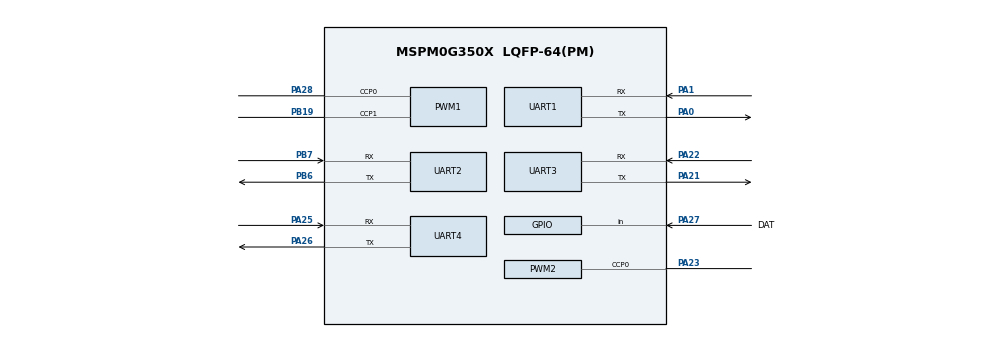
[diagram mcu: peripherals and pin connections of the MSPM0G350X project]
/**
 * @cliArgs --device "MSPM0G350X" --package "LQFP-64(PM)" --part "Default" --product "mspm0_sdk@2.01.00.03"
 * @versions {"tool":"1.20.0+3587"}
 */

/**
 * Import the modules used in this configuration.
 */
const GPIO    = scripting.addModule("/ti/driverlib/GPIO", {}, false);
const GPIO1   = GPIO.addInstance();
const GPIO2   = GPIO.addInstance();
const GPIO3   = GPIO.addInstance();
const GPIO4   = GPIO.addInstance();
const GPIO5   = GPIO.addInstance();
const GPIO6   = GPIO.addInstance();
const GPIO7   = GPIO.addInstance();
const PWM     = scripting.addModule("/ti/driverlib/PWM", {}, false);
const PWM1    = PWM.addInstance();
const PWM2    = PWM.addInstance();
const SYSCTL  = scripting.addModule("/ti/driverlib/SYSCTL");
const SYSTICK = scripting.addModule("/ti/driverlib/SYSTICK");
const TIMER   = scripting.addModule("/ti/driverlib/TIMER", {}, false);
const TIMER1  = TIMER.addInstance();
const UART    = scripting.addModule("/ti/driverlib/UART", {}, false);
const UART1   = UART.addInstance();
const UART2   = UART.addInstance();
const UART3   = UART.addInstance();
const UART4   = UART.addInstance();

/**
 * Write custom configuration values to the imported modules.
 */
const gate7  = system.clockTree["MFCLKGATE"];
gate7.enable = true;

GPIO1.$name                          = "GPIO_MOTOR";
GPIO1.associatedPins.create(4);
GPIO1.associatedPins[0].assignedPort = "PORTA";
GPIO1.associatedPins[0].initialValue = "SET";
GPIO1.associatedPins[0].$name        = "PIN_FL1";
GPIO1.associatedPins[0].assignedPin  = "2";
GPIO1.associatedPins[1].assignedPort = "PORTA";
GPIO1.associatedPins[1].initialValue = "SET";
GPIO1.associatedPins[1].$name        = "PIN_FL2";
GPIO1.associatedPins[1].assignedPin  = "31";
GPIO1.associatedPins[2].$name        = "PIN_FR1";
GPIO1.associatedPins[2].assignedPort = "PORTB";
GPIO1.associatedPins[2].assignedPin  = "24";
GPIO1.associatedPins[3].$name        = "PIN_FR2";
GPIO1.associatedPins[3].assignedPort = "PORTB";
GPIO1.associatedPins[3].assignedPin  = "20";

const Board = scripting.addModule("/ti/driverlib/Board", {}, false);

GPIO2.$name                          = "GPIO_Encoder";
GPIO2.associatedPins.create(4);
GPIO2.associatedPins[0].$name        = "PIN_Left_A";
GPIO2.associatedPins[0].direction    = "INPUT";
GPIO2.associatedPins[0].assignedPort = "PORTA";
GPIO2.associatedPins[0].assignedPin  = "7";
GPIO2.associatedPins[0].interruptEn  = true;
GPIO2.associatedPins[0].polarity     = "RISE";
GPIO2.associatedPins[1].$name        = "PIN_Right_A";
GPIO2.associatedPins[1].direction    = "INPUT";
GPIO2.associatedPins[1].assignedPort = "PORTB";
GPIO2.associatedPins[1].assignedPin  = "3";
GPIO2.associatedPins[1].interruptEn  = true;
GPIO2.associatedPins[1].polarity     = "RISE";
GPIO2.associatedPins[2].$name        = "PIN_Left_B";
GPIO2.associatedPins[2].direction    = "INPUT";
GPIO2.associatedPins[2].assignedPort = "PORTB";
GPIO2.associatedPins[2].assignedPin  = "18";
GPIO2.associatedPins[3].$name        = "PIN_Right_B";
GPIO2.associatedPins[3].direction    = "INPUT";
GPIO2.associatedPins[3].assignedPort = "PORTB";
GPIO2.associatedPins[3].assignedPin  = "2";

GPIO3.$name                          = "GPIO_SWITCHES";
GPIO3.associatedPins[0].$name        = "USER_SWITCH_1";
GPIO3.associatedPins[0].direction    = "INPUT";
GPIO3.associatedPins[0].assignedPort = "PORTA";
GPIO3.associatedPins[0].assignedPin  = "18";

GPIO4.$name                          = "GPIO_LEDS";
GPIO4.associatedPins[0].$name        = "USR_LED_1";
GPIO4.associatedPins[0].initialValue = "SET";
GPIO4.associatedPins[0].assignedPort = "PORTA";
GPIO4.associatedPins[0].assignedPin  = "14";

GPIO5.$name                               = "GPIO_GanWei";
GPIO5.port                                = "PORTA";
GPIO5.associatedPins.create(2);
GPIO5.associatedPins[0].$name             = "CLK";
GPIO5.associatedPins[0].assignedPin       = "24";
GPIO5.associatedPins[1].$name             = "DAT";
GPIO5.associatedPins[1].direction         = "INPUT";
GPIO5.associatedPins[1].internalResistor  = "PULL_UP";
GPIO5.associatedPins[1].assignedPin       = "27";
GPIO5.associatedPins[1].interruptEn       = true;
GPIO5.associatedPins[1].interruptPriority = "0";
GPIO5.associatedPins[1].polarity          = "RISE";
GPIO5.associatedPins[1].pin.$assign       = "PA27";

GPIO6.$name                          = "GPIO_Light";
GPIO6.associatedPins.create(5);
GPIO6.associatedPins[0].$name        = "PIN_Light_1";
GPIO6.associatedPins[0].direction    = "INPUT";
GPIO6.associatedPins[0].assignedPort = "PORTA";
GPIO6.associatedPins[0].assignedPin  = "8";
GPIO6.associatedPins[1].$name        = "PIN_Light_2";
GPIO6.associatedPins[1].direction    = "INPUT";
GPIO6.associatedPins[1].assignedPort = "PORTA";
GPIO6.associatedPins[1].assignedPin  = "9";
GPIO6.associatedPins[2].$name        = "PIN_Light_3";
GPIO6.associatedPins[2].direction    = "INPUT";
GPIO6.associatedPins[2].assignedPort = "PORTA";
GPIO6.associatedPins[2].assignedPin  = "13";
GPIO6.associatedPins[3].$name        = "PIN_Light_4";
GPIO6.associatedPins[3].direction    = "INPUT";
GPIO6.associatedPins[3].assignedPort = "PORTA";
GPIO6.associatedPins[3].assignedPin  = "12";
GPIO6.associatedPins[4].$name        = "PIN_Light_5";
GPIO6.associatedPins[4].direction    = "INPUT";
GPIO6.associatedPins[4].assignedPort = "PORTA";
GPIO6.associatedPins[4].assignedPin  = "15";

GPIO7.$name                          = "GPIO_Jidianqi";
GPIO7.associatedPins[0].$name        = "GPIO_Ji";
GPIO7.associatedPins[0].initialValue = "SET";
GPIO7.associatedPins[0].assignedPort = "PORTA";
GPIO7.associatedPins[0].assignedPin  = "16";

PWM1.$name                              = "PWM_MOTOR";
PWM1.timerCount                         = 32000;
PWM1.timerStartTimer                    = true;
PWM1.peripheral.$assign                 = "TIMG7";
PWM1.peripheral.ccp0Pin.$assign         = "PA28";
PWM1.peripheral.ccp1Pin.$assign         = "PB19";
PWM1.PWM_CHANNEL_0.$name                = "ti_driverlib_pwm_PWMTimerCC0";
PWM1.PWM_CHANNEL_0.ccValue              = 3199;
PWM1.PWM_CHANNEL_1.$name                = "ti_driverlib_pwm_PWMTimerCC1";
PWM1.ccp0PinConfig.direction            = scripting.forceWrite("OUTPUT");
PWM1.ccp0PinConfig.hideOutputInversion  = scripting.forceWrite(false);
PWM1.ccp0PinConfig.onlyInternalResistor = scripting.forceWrite(false);
PWM1.ccp0PinConfig.passedPeripheralType = scripting.forceWrite("Digital");
PWM1.ccp0PinConfig.$name                = "ti_driverlib_gpio_GPIOPinGeneric10";
PWM1.ccp1PinConfig.direction            = scripting.forceWrite("OUTPUT");
PWM1.ccp1PinConfig.hideOutputInversion  = scripting.forceWrite(false);
PWM1.ccp1PinConfig.onlyInternalResistor = scripting.forceWrite(false);
PWM1.ccp1PinConfig.passedPeripheralType = scripting.forceWrite("Digital");
PWM1.ccp1PinConfig.$name                = "ti_driverlib_gpio_GPIOPinGeneric11";

PWM2.$name                              = "PWM_SERVO";
PWM2.clockPrescale                      = 20;
PWM2.timerStartTimer                    = true;
PWM2.timerCount                         = 32000;
PWM2.ccIndex                            = [0];
PWM2.peripheral.$assign                 = "TIMG0";
PWM2.peripheral.ccp0Pin.$assign         = "PA23";
PWM2.PWM_CHANNEL_0.$name                = "ti_driverlib_pwm_PWMTimerCC2";
PWM2.PWM_CHANNEL_0.ccValue              = 3199;
PWM2.ccp0PinConfig.direction            = scripting.forceWrite("OUTPUT");
PWM2.ccp0PinConfig.hideOutputInversion  = scripting.forceWrite(false);
PWM2.ccp0PinConfig.onlyInternalResistor = scripting.forceWrite(false);
PWM2.ccp0PinConfig.passedPeripheralType = scripting.forceWrite("Digital");
PWM2.ccp0PinConfig.$name                = "ti_driverlib_gpio_GPIOPinGeneric12";

SYSCTL.clockTreeEn           = true;
SYSCTL.powerPolicy           = "STANDBY0";
SYSCTL.forceDefaultClkConfig = true;

SYSTICK.interruptEnable   = true;
SYSTICK.systickEnable     = true;
SYSTICK.periodEnable      = true;
SYSTICK.interruptPriority = "0";
SYSTICK.period            = 32000;

TIMER1.$name            = "TIMER_0";
TIMER1.timerClkPrescale = 40;
TIMER1.timerClkDiv      = 8;
TIMER1.timerStartTimer  = true;
TIMER1.timerMode        = "PERIODIC";
TIMER1.timerPeriod      = "50 ms";

UART1.$name                    = "UART_0";
UART1.enableFIFO               = true;
UART1.rxFifoThreshold          = "DL_UART_RX_FIFO_LEVEL_3_4_FULL";
UART1.rxTimeoutValue           = 15;
UART1.enableDMARX              = false;
UART1.enableDMATX              = false;
UART1.enabledInterrupts        = ["RX"];
UART1.peripheral.$assign       = "UART0";
UART1.peripheral.rxPin.$assign = "PA1";
UART1.peripheral.txPin.$assign = "PA0";
UART1.txPinConfig.$name        = "ti_driverlib_gpio_GPIOPinGeneric0";
UART1.rxPinConfig.$name        = "ti_driverlib_gpio_GPIOPinGeneric1";

UART2.$name                    = "UART_1";
UART2.enabledInterrupts        = ["RX"];
UART2.targetBaudRate           = 115200;
UART2.peripheral.$assign       = "UART1";
UART2.peripheral.rxPin.$assign = "PB7";
UART2.peripheral.txPin.$assign = "PB6";
UART2.txPinConfig.$name        = "ti_driverlib_gpio_GPIOPinGeneric4";
UART2.rxPinConfig.$name        = "ti_driverlib_gpio_GPIOPinGeneric5";

UART3.$name                    = "UART_2";
UART3.targetBaudRate           = 115200;
UART3.enabledInterrupts        = ["RX"];
UART3.peripheral.$assign       = "UART2";
UART3.peripheral.rxPin.$assign = "PA22";
UART3.peripheral.txPin.$assign = "PA21";
UART3.txPinConfig.$name        = "ti_driverlib_gpio_GPIOPinGeneric6";
UART3.rxPinConfig.$name        = "ti_driverlib_gpio_GPIOPinGeneric7";

UART4.$name                    = "UART_3";
UART4.enabledInterrupts        = ["RX"];
UART4.targetBaudRate           = 115200;
UART4.peripheral.$assign       = "UART3";
UART4.peripheral.rxPin.$assign = "PA25";
UART4.peripheral.txPin.$assign = "PA26";
UART4.txPinConfig.$name        = "ti_driverlib_gpio_GPIOPinGeneric8";
UART4.rxPinConfig.$name        = "ti_driverlib_gpio_GPIOPinGeneric9";

/**
 * Pinmux solution for unlocked pins/peripherals. This ensures that minor changes to the automatic solver in a future
 * version of the tool will not impact the pinmux you originally saw.  These lines can be completely deleted in order to
 * re-solve from scratch.
 */
GPIO1.associatedPins[0].pin.$suggestSolution = "PA2";
GPIO1.associatedPins[1].pin.$suggestSolution = "PA31";
GPIO1.associatedPins[2].pin.$suggestSolution = "PB24";
GPIO1.associatedPins[3].pin.$suggestSolution = "PB20";
Board.peripheral.$suggestSolution            = "DEBUGSS";
Board.peripheral.swclkPin.$suggestSolution   = "PA20";
Board.peripheral.swdioPin.$suggestSolution   = "PA19";
GPIO2.associatedPins[0].pin.$suggestSolution = "PA7";
GPIO2.associatedPins[1].pin.$suggestSolution = "PB3";
GPIO2.associatedPins[2].pin.$suggestSolution = "PB18";
GPIO2.associatedPins[3].pin.$suggestSolution = "PB2";
GPIO3.associatedPins[0].pin.$suggestSolution = "PA18";
GPIO4.associatedPins[0].pin.$suggestSolution = "PA14";
GPIO5.associatedPins[0].pin.$suggestSolution = "PA24";
GPIO6.associatedPins[0].pin.$suggestSolution = "PA8";
GPIO6.associatedPins[1].pin.$suggestSolution = "PA9";
GPIO6.associatedPins[2].pin.$suggestSolution = "PA13";
GPIO6.associatedPins[3].pin.$suggestSolution = "PA12";
GPIO6.associatedPins[4].pin.$suggestSolution = "PA15";
GPIO7.associatedPins[0].pin.$suggestSolution = "PA16";
TIMER1.peripheral.$suggestSolution           = "TIMA0";
